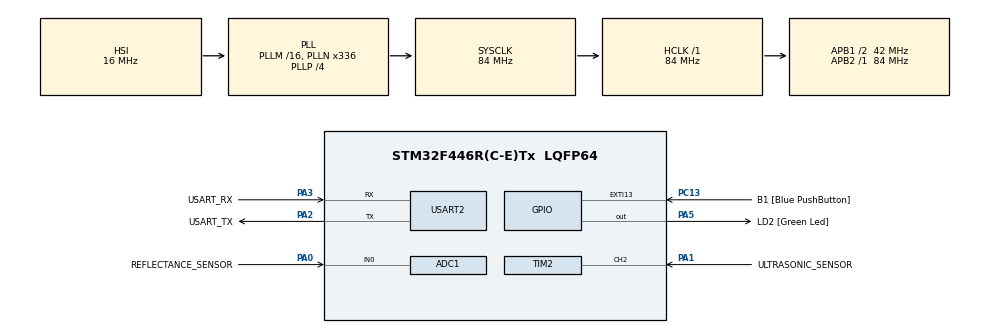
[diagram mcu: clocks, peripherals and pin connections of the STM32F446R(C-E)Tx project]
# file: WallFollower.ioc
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ADC1.Channel-0\#ChannelRegularConversion=ADC_CHANNEL_0
ADC1.NbrOfConversionFlag=1
ADC1.Rank-0\#ChannelRegularConversion=1
ADC1.SamplingTime-0\#ChannelRegularConversion=ADC_SAMPLETIME_3CYCLES
ADC1.master=1
Mcu.Family=STM32F4
Mcu.Name=STM32F446R(C-E)Tx
Mcu.Package=LQFP64
NVIC.PriorityGroup=NVIC_PRIORITYGROUP_0
PA0-WKUP.GPIO_Label=REFLECTANCE_SENSOR
PA0-WKUP.Signal=ADCx_IN0
PA1.GPIO_Label=ULTRASONIC_SENSOR
PA1.Signal=S_TIM2_CH2
PA13.GPIO_Label=TMS
PA13.Signal=SYS_JTMS-SWDIO
PA14.GPIO_Label=TCK
PA14.Signal=SYS_JTCK-SWCLK
PA2.GPIO_Label=USART_TX
PA2.Mode=Asynchronous
PA2.Signal=USART2_TX
PA3.GPIO_Label=USART_RX
PA3.Mode=Asynchronous
PA3.Signal=USART2_RX
PA5.GPIO_Label=LD2 [Green Led]
PA5.Signal=GPIO_Output
PB3.GPIO_Label=SWO
PB3.Signal=SYS_JTDO-SWO
PC13.GPIO_Label=B1 [Blue PushButton]
PC13.GPIO_ModeDefaultEXTI=GPIO_MODE_EVT_RISING
PC13.Signal=GPXTI13
PC14-OSC32_IN.Signal=RCC_OSC32_IN
PC15-OSC32_OUT.Signal=RCC_OSC32_OUT
PH0-OSC_IN.Signal=RCC_OSC_IN
PH1-OSC_OUT.Signal=RCC_OSC_OUT
ProjectManager.HeapSize=0x200
ProjectManager.StackSize=0x400
ProjectManager.TargetToolchain=TrueSTUDIO
RCC.AHBFreq_Value=84000000
RCC.APB1CLKDivider=RCC_HCLK_DIV2
RCC.APB1Freq_Value=42000000
RCC.APB1TimFreq_Value=84000000
RCC.APB2Freq_Value=84000000
RCC.APB2TimFreq_Value=84000000
RCC.CortexFreq_Value=84000000
RCC.FLatency-AdvancedSettings=FLASH_LATENCY_2
RCC.HCLKFreq_Value=84000000
RCC.HSE_VALUE=8000000
RCC.HSI_VALUE=16000000
RCC.LSE_VALUE=32768
RCC.PLLN=336
RCC.PLLP=RCC_PLLP_DIV4
RCC.SYSCLKFreq_VALUE=84000000
RCC.SYSCLKSource=RCC_SYSCLKSOURCE_PLLCLK
RCC.USBFreq_Value=168000000
RCC.VCOOutputFreq_Value=336000000
SH.ADCx_IN0.0=ADC1_IN0,IN0
SH.S_TIM2_CH2.0=TIM2_CH2,Input_Capture2_from_TI2
TIM2.Channel-Input_Capture2_from_TI2=TIM_CHANNEL_2
TIM2.TIM_MasterOutputTrigger=TIM_TRGO_RESET
VP_TIM2_VS_OPM.Mode=OPM_bit
board=NUCLEO-F446RE

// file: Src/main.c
/**
  ******************************************************************************
  * File Name          : main.c
  * Description        : Main program body
  ******************************************************************************
  *
  * COPYRIGHT(c) 2017 STMicroelectronics
  *
  * Redistribution and use in source and binary forms, with or without modification,
  * are permitted provided that the following conditions are met:
  *   1. Redistributions of source code must retain the above copyright notice,
  *      this list of conditions and the following disclaimer.
  *   2. Redistributions in binary form must reproduce the above copyright notice,
  *      this list of conditions and the following disclaimer in the documentation
  *      and/or other materials provided with the distribution.
  *   3. Neither the name of STMicroelectronics nor the names of its contributors
  *      may be used to endorse or promote products derived from this software
  *      without specific prior written permission.
  *
  * THIS SOFTWARE IS PROVIDED BY THE COPYRIGHT HOLDERS AND CONTRIBUTORS "AS IS"
  * AND ANY EXPRESS OR IMPLIED WARRANTIES, INCLUDING, BUT NOT LIMITED TO, THE
  * IMPLIED WARRANTIES OF MERCHANTABILITY AND FITNESS FOR A PARTICULAR PURPOSE ARE
  * DISCLAIMED. IN NO EVENT SHALL THE COPYRIGHT HOLDER OR CONTRIBUTORS BE LIABLE
  * FOR ANY DIRECT, INDIRECT, INCIDENTAL, SPECIAL, EXEMPLARY, OR CONSEQUENTIAL
  * DAMAGES (INCLUDING, BUT NOT LIMITED TO, PROCUREMENT OF SUBSTITUTE GOODS OR
  * SERVICES; LOSS OF USE, DATA, OR PROFITS; OR BUSINESS INTERRUPTION) HOWEVER
  * CAUSED AND ON ANY THEORY OF LIABILITY, WHETHER IN CONTRACT, STRICT LIABILITY,
  * OR TORT (INCLUDING NEGLIGENCE OR OTHERWISE) ARISING IN ANY WAY OUT OF THE USE
  * OF THIS SOFTWARE, EVEN IF ADVISED OF THE POSSIBILITY OF SUCH DAMAGE.
  *
  ******************************************************************************
  */
#include "main.h"
#include "stm32f4xx_hal.h"
#include "adc.h"
#include "tim.h"
#include "usart.h"
#include "gpio.h"

/* USER CODE BEGIN Includes */
#include "system.h"
#include "reflectancesensor.h"
/* USER CODE END Includes */

/* USER CODE BEGIN PV */
/* Private variables ---------------------------------------------------------*/
static System l_system;
static ReflectanceSensor l_reflectanceSensor;
/* USER CODE END PV */

void SystemClock_Config(void);
void Error_Handler(void);

/* USER CODE BEGIN PFP */
/* Private function prototypes -----------------------------------------------*/
void QF_onStartup() {}
void Q_onAssert(char_t const * const module, int_t location) {}
void QV_onIdle() { QF_INT_ENABLE(); }
/* USER CODE END PFP */

int main(void)
{

  /* USER CODE BEGIN 1 */
  static QEvt const *system_queueSto[10];
  /* USER CODE END 1 */

  /* MCU Configuration----------------------------------------------------------*/

  /* Reset of all peripherals, Initializes the Flash interface and the Systick. */
  HAL_Init();

  /* Configure the system clock */
  SystemClock_Config();

  /* Initialize all configured peripherals */
  MX_GPIO_Init();
  MX_USART2_UART_Init();
  MX_TIM2_Init();
  MX_ADC1_Init();

  /* USER CODE BEGIN 2 */
  System_ctor(&l_system);
  ReflectanceSensor_ctor(&l_reflectanceSensor, &hadc1, ADC_CHANNEL_0);
  QF_init();

  QActive_start(&l_system, 1U, system_queueSto, Q_DIM(system_queueSto), (void *)0, 1024U, (QEvt*)0);

  return QF_run();
  /* USER CODE END 2 */

  /* Infinite loop */

}

/** System Clock Configuration
*/
void SystemClock_Config(void)
{

  RCC_OscInitTypeDef RCC_OscInitStruct;
  RCC_ClkInitTypeDef RCC_ClkInitStruct;

    /**Configure the main internal regulator output voltage
    */
  __HAL_RCC_PWR_CLK_ENABLE();

  __HAL_PWR_VOLTAGESCALING_CONFIG(PWR_REGULATOR_VOLTAGE_SCALE3);

    /**Initializes the CPU, AHB and APB busses clocks
    */
  RCC_OscInitStruct.OscillatorType = RCC_OSCILLATORTYPE_HSI;
  RCC_OscInitStruct.HSIState = RCC_HSI_ON;
  RCC_OscInitStruct.HSICalibrationValue = 16;
  RCC_OscInitStruct.PLL.PLLState = RCC_PLL_ON;
  RCC_OscInitStruct.PLL.PLLSource = RCC_PLLSOURCE_HSI;
  RCC_OscInitStruct.PLL.PLLM = 16;
  RCC_OscInitStruct.PLL.PLLN = 336;
  RCC_OscInitStruct.PLL.PLLP = RCC_PLLP_DIV4;
  RCC_OscInitStruct.PLL.PLLQ = 2;
  RCC_OscInitStruct.PLL.PLLR = 2;
  if (HAL_RCC_OscConfig(&RCC_OscInitStruct) != HAL_OK)
  {
    Error_Handler();
  }

    /**Initializes the CPU, AHB and APB busses clocks
    */
  RCC_ClkInitStruct.ClockType = RCC_CLOCKTYPE_HCLK|RCC_CLOCKTYPE_SYSCLK
                              |RCC_CLOCKTYPE_PCLK1|RCC_CLOCKTYPE_PCLK2;
  RCC_ClkInitStruct.SYSCLKSource = RCC_SYSCLKSOURCE_PLLCLK;
  RCC_ClkInitStruct.AHBCLKDivider = RCC_SYSCLK_DIV1;
  RCC_ClkInitStruct.APB1CLKDivider = RCC_HCLK_DIV2;
  RCC_ClkInitStruct.APB2CLKDivider = RCC_HCLK_DIV1;

  if (HAL_RCC_ClockConfig(&RCC_ClkInitStruct, FLASH_LATENCY_2) != HAL_OK)
  {
    Error_Handler();
  }

    /**Configure the Systick interrupt time
    */
  HAL_SYSTICK_Config(HAL_RCC_GetHCLKFreq()/1000);

    /**Configure the Systick
    */
  HAL_SYSTICK_CLKSourceConfig(SYSTICK_CLKSOURCE_HCLK);

  /* SysTick_IRQn interrupt configuration */
  HAL_NVIC_SetPriority(SysTick_IRQn, 0, 0);
}

void Error_Handler(void)
{
  while(1)
  {
  }
}

/************************ (C) COPYRIGHT STMicroelectronics *****END OF FILE****/
